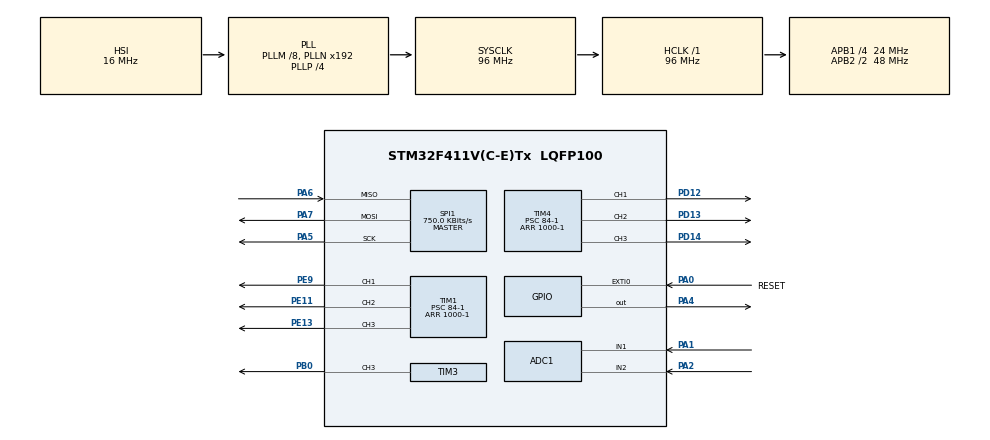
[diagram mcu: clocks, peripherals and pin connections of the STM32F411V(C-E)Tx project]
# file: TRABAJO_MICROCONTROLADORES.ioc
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ADC1.Channel-0\#ChannelRegularConversion=ADC_CHANNEL_1
ADC1.Channel-1\#ChannelRegularConversion=ADC_CHANNEL_2
ADC1.NbrOfConversion=2
ADC1.NbrOfConversionFlag=1
ADC1.Rank-0\#ChannelRegularConversion=1
ADC1.Rank-1\#ChannelRegularConversion=2
ADC1.SamplingTime-0\#ChannelRegularConversion=ADC_SAMPLETIME_84CYCLES
ADC1.SamplingTime-1\#ChannelRegularConversion=ADC_SAMPLETIME_84CYCLES
ADC1.ScanConvMode=ENABLE
ADC1.master=1
Mcu.Family=STM32F4
Mcu.Name=STM32F411V(C-E)Tx
Mcu.Package=LQFP100
NVIC.EXTI0_IRQn=true\:0\:0\:false\:false\:true\:true\:true\:true
NVIC.PriorityGroup=NVIC_PRIORITYGROUP_0
PA0-WKUP.GPIO_Label=RESET
PA0-WKUP.Signal=GPXTI0
PA1.Signal=ADCx_IN1
PA2.Signal=ADCx_IN2
PA4.Signal=GPIO_Output
PA5.Mode=Full_Duplex_Master
PA5.Signal=SPI1_SCK
PA6.Mode=Full_Duplex_Master
PA6.Signal=SPI1_MISO
PA7.Mode=Full_Duplex_Master
PA7.Signal=SPI1_MOSI
PB0.Signal=S_TIM3_CH3
PD12.Signal=S_TIM4_CH1
PD13.Signal=S_TIM4_CH2
PD14.Signal=S_TIM4_CH3
PE11.Signal=S_TIM1_CH2
PE13.Signal=S_TIM1_CH3
PE9.Signal=S_TIM1_CH1
ProjectManager.HeapSize=0x200
ProjectManager.StackSize=0x400
ProjectManager.TargetToolchain=STM32CubeIDE
RCC.48MHZClocksFreq_Value=48000000
RCC.AHBFreq_Value=96000000
RCC.APB1CLKDivider=RCC_HCLK_DIV4
RCC.APB1Freq_Value=24000000
RCC.APB1TimFreq_Value=48000000
RCC.APB2CLKDivider=RCC_HCLK_DIV2
RCC.APB2Freq_Value=48000000
RCC.APB2TimFreq_Value=96000000
RCC.CortexFreq_Value=96000000
RCC.HCLKFreq_Value=96000000
RCC.HSE_VALUE=8000000
RCC.HSI_VALUE=16000000
RCC.LSE_VALUE=32768
RCC.PLLI2SM=5
RCC.PLLI2SN=200
RCC.PLLM=8
RCC.PLLP=RCC_PLLP_DIV4
RCC.PLLQ=8
RCC.SYSCLKFreq_VALUE=96000000
RCC.SYSCLKSource=RCC_SYSCLKSOURCE_PLLCLK
RCC.VCOOutputFreq_Value=384000000
SH.ADCx_IN1.0=ADC1_IN1,IN1
SH.ADCx_IN2.0=ADC1_IN2,IN2
SH.S_TIM1_CH1.0=TIM1_CH1,PWM Generation1 CH1
SH.S_TIM1_CH2.0=TIM1_CH2,PWM Generation2 CH2
SH.S_TIM1_CH3.0=TIM1_CH3,PWM Generation3 CH3
SH.S_TIM3_CH3.0=TIM3_CH3,PWM Generation3 CH3
SH.S_TIM4_CH1.0=TIM4_CH1,PWM Generation1 CH1
SH.S_TIM4_CH2.0=TIM4_CH2,PWM Generation2 CH2
SH.S_TIM4_CH3.0=TIM4_CH3,PWM Generation3 CH3
SPI1.BaudRatePrescaler=SPI_BAUDRATEPRESCALER_64
SPI1.CalculateBaudRate=750.0 KBits/s
SPI1.Direction=SPI_DIRECTION_2LINES
SPI1.Mode=SPI_MODE_MASTER
SPI1.VirtualType=VM_MASTER
TIM1.AutoReloadPreload=TIM_AUTORELOAD_PRELOAD_ENABLE
TIM1.Channel-PWM\ Generation1\ CH1=TIM_CHANNEL_1
TIM1.Channel-PWM\ Generation2\ CH2=TIM_CHANNEL_2
TIM1.Channel-PWM\ Generation3\ CH3=TIM_CHANNEL_3
TIM1.Period=1000-1
TIM1.Prescaler=84-1
TIM3.AutoReloadPreload=TIM_AUTORELOAD_PRELOAD_ENABLE
TIM3.Channel-PWM\ Generation3\ CH3=TIM_CHANNEL_3
TIM3.Period=1000-1
TIM3.Prescaler=84-1
TIM4.AutoReloadPreload=TIM_AUTORELOAD_PRELOAD_ENABLE
TIM4.Channel-PWM\ Generation1\ CH1=TIM_CHANNEL_1
TIM4.Channel-PWM\ Generation2\ CH2=TIM_CHANNEL_2
TIM4.Channel-PWM\ Generation3\ CH3=TIM_CHANNEL_3
TIM4.Period=1000-1
TIM4.Prescaler=84-1
VP_TIM1_VS_ClockSourceINT.Mode=Internal
VP_TIM3_VS_ClockSourceINT.Mode=Internal
VP_TIM4_VS_ClockSourceINT.Mode=Internal
board=STM32F411E-DISCO

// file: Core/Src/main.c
/* USER CODE BEGIN Header */
/**
  ******************************************************************************
  * @file           : main.c
  * @brief          : Main program body
  ******************************************************************************
  * @attention
  *
  * Copyright (c) 2026 STMicroelectronics.
  * All rights reserved.
  *
  * This software is licensed under terms that can be found in the LICENSE file
  * in the root directory of this software component.
  * If no LICENSE file comes with this software, it is provided AS-IS.
  *
  ******************************************************************************
  */
/* USER CODE END Header */
#include "main.h"
#include "Inputs.h"
#include "Coordinador.h"
#include "Orden_Juego.h"
#include "Zumbador.h"

#include <stdlib.h>

ADC_HandleTypeDef hadc1;

SPI_HandleTypeDef hspi1;

TIM_HandleTypeDef htim1;
TIM_HandleTypeDef htim3;
TIM_HandleTypeDef htim4;

void SystemClock_Config(void);
static void MX_GPIO_Init(void);
static void MX_ADC1_Init(void);
static void MX_TIM1_Init(void);
static void MX_SPI1_Init(void);
static void MX_TIM3_Init(void);
static void MX_TIM4_Init(void);

int main(void)
{

  HAL_Init();
  SystemClock_Config();

  MX_GPIO_Init();
  MX_ADC1_Init();
  MX_TIM1_Init();
  MX_SPI1_Init();
  MX_TIM3_Init();
  MX_TIM4_Init();

  srand(HAL_GetTick());

  Inputs_Init();
  Coordinador_Init();
  Zumbador_Init();
  LEDRGB_Init();
  MAX7219_Init();
  while (1)
  {
    Coordinador_Update();
    HAL_Delay(5);
  }
  /* USER CODE END 3 */
}

void SystemClock_Config(void)
{
  RCC_OscInitTypeDef RCC_OscInitStruct = {0};
  RCC_ClkInitTypeDef RCC_ClkInitStruct = {0};

  /** Configure the main internal regulator output voltage
  */
  __HAL_RCC_PWR_CLK_ENABLE();
  __HAL_PWR_VOLTAGESCALING_CONFIG(PWR_REGULATOR_VOLTAGE_SCALE1);

  /** Initializes the RCC Oscillators according to the specified parameters
  * in the RCC_OscInitTypeDef structure.
  */
  RCC_OscInitStruct.OscillatorType = RCC_OSCILLATORTYPE_HSI;
  RCC_OscInitStruct.HSIState = RCC_HSI_ON;
  RCC_OscInitStruct.HSICalibrationValue = RCC_HSICALIBRATION_DEFAULT;
  RCC_OscInitStruct.PLL.PLLState = RCC_PLL_ON;
  RCC_OscInitStruct.PLL.PLLSource = RCC_PLLSOURCE_HSI;
  RCC_OscInitStruct.PLL.PLLM = 8;
  RCC_OscInitStruct.PLL.PLLN = 192;
  RCC_OscInitStruct.PLL.PLLP = RCC_PLLP_DIV4;
  RCC_OscInitStruct.PLL.PLLQ = 8;
  if (HAL_RCC_OscConfig(&RCC_OscInitStruct) != HAL_OK)
  {
    Error_Handler();
  }

  /** Initializes the CPU, AHB and APB buses clocks
  */
  RCC_ClkInitStruct.ClockType = RCC_CLOCKTYPE_HCLK|RCC_CLOCKTYPE_SYSCLK
                              |RCC_CLOCKTYPE_PCLK1|RCC_CLOCKTYPE_PCLK2;
  RCC_ClkInitStruct.SYSCLKSource = RCC_SYSCLKSOURCE_PLLCLK;
  RCC_ClkInitStruct.AHBCLKDivider = RCC_SYSCLK_DIV1;
  RCC_ClkInitStruct.APB1CLKDivider = RCC_HCLK_DIV4;
  RCC_ClkInitStruct.APB2CLKDivider = RCC_HCLK_DIV2;

  if (HAL_RCC_ClockConfig(&RCC_ClkInitStruct, FLASH_LATENCY_3) != HAL_OK)
  {
    Error_Handler();
  }
}

static void MX_ADC1_Init(void)
{

  ADC_ChannelConfTypeDef sConfig = {0};

  /** Configure the global features of the ADC (Clock, Resolution, Data Alignment and number of conversion)
  */
  hadc1.Instance = ADC1;
  hadc1.Init.ClockPrescaler = ADC_CLOCK_SYNC_PCLK_DIV2;
  hadc1.Init.Resolution = ADC_RESOLUTION_12B;
  hadc1.Init.ScanConvMode = DISABLE;
  hadc1.Init.ContinuousConvMode = DISABLE;
  hadc1.Init.DiscontinuousConvMode = DISABLE;
  hadc1.Init.ExternalTrigConvEdge = ADC_EXTERNALTRIGCONVEDGE_NONE;
  hadc1.Init.ExternalTrigConv = ADC_SOFTWARE_START;
  hadc1.Init.DataAlign = ADC_DATAALIGN_RIGHT;
  hadc1.Init.NbrOfConversion = 1;
  hadc1.Init.DMAContinuousRequests = DISABLE;
  hadc1.Init.EOCSelection = ADC_EOC_SINGLE_CONV;
  if (HAL_ADC_Init(&hadc1) != HAL_OK)
  {
    Error_Handler();
  }

  /** Configure for the selected ADC regular channel its corresponding rank in the sequencer and its sample time.
  */
  sConfig.Channel = ADC_CHANNEL_1;
  sConfig.Rank = 1;
  sConfig.SamplingTime = ADC_SAMPLETIME_84CYCLES;
  if (HAL_ADC_ConfigChannel(&hadc1, &sConfig) != HAL_OK)
  {
    Error_Handler();
  }

  /** Configure for the selected ADC regular channel its corresponding rank in the sequencer and its sample time.
  */
  sConfig.Channel = ADC_CHANNEL_2;
  sConfig.Rank = 2;
  if (HAL_ADC_ConfigChannel(&hadc1, &sConfig) != HAL_OK)
  {
    Error_Handler();
  }

}

static void MX_SPI1_Init(void)
{

  /* SPI1 parameter configuration*/
  hspi1.Instance = SPI1;
  hspi1.Init.Mode = SPI_MODE_MASTER;
  hspi1.Init.Direction = SPI_DIRECTION_2LINES;
  hspi1.Init.DataSize = SPI_DATASIZE_8BIT;
  hspi1.Init.CLKPolarity = SPI_POLARITY_LOW;
  hspi1.Init.CLKPhase = SPI_PHASE_1EDGE;
  hspi1.Init.NSS = SPI_NSS_SOFT;
  hspi1.Init.BaudRatePrescaler = SPI_BAUDRATEPRESCALER_64;
  hspi1.Init.FirstBit = SPI_FIRSTBIT_MSB;
  hspi1.Init.TIMode = SPI_TIMODE_DISABLE;
  hspi1.Init.CRCCalculation = SPI_CRCCALCULATION_DISABLE;
  hspi1.Init.CRCPolynomial = 10;
  if (HAL_SPI_Init(&hspi1) != HAL_OK)
  {
    Error_Handler();
  }

}

static void MX_TIM1_Init(void)
{

  TIM_ClockConfigTypeDef sClockSourceConfig = {0};
  TIM_MasterConfigTypeDef sMasterConfig = {0};
  TIM_OC_InitTypeDef sConfigOC = {0};
  TIM_BreakDeadTimeConfigTypeDef sBreakDeadTimeConfig = {0};

  htim1.Instance = TIM1;
  htim1.Init.Prescaler = 84-1;
  htim1.Init.CounterMode = TIM_COUNTERMODE_UP;
  htim1.Init.Period = 1000-1;
  htim1.Init.ClockDivision = TIM_CLOCKDIVISION_DIV1;
  htim1.Init.RepetitionCounter = 0;
  htim1.Init.AutoReloadPreload = TIM_AUTORELOAD_PRELOAD_ENABLE;
  if (HAL_TIM_Base_Init(&htim1) != HAL_OK)
  {
    Error_Handler();
  }
  sClockSourceConfig.ClockSource = TIM_CLOCKSOURCE_INTERNAL;
  if (HAL_TIM_ConfigClockSource(&htim1, &sClockSourceConfig) != HAL_OK)
  {
    Error_Handler();
  }
  if (HAL_TIM_PWM_Init(&htim1) != HAL_OK)
  {
    Error_Handler();
  }
  sMasterConfig.MasterOutputTrigger = TIM_TRGO_RESET;
  sMasterConfig.MasterSlaveMode = TIM_MASTERSLAVEMODE_DISABLE;
  if (HAL_TIMEx_MasterConfigSynchronization(&htim1, &sMasterConfig) != HAL_OK)
  {
    Error_Handler();
  }
  sConfigOC.OCMode = TIM_OCMODE_PWM1;
  sConfigOC.Pulse = 0;
  sConfigOC.OCPolarity = TIM_OCPOLARITY_HIGH;
  sConfigOC.OCNPolarity = TIM_OCNPOLARITY_HIGH;
  sConfigOC.OCFastMode = TIM_OCFAST_DISABLE;
  sConfigOC.OCIdleState = TIM_OCIDLESTATE_RESET;
  sConfigOC.OCNIdleState = TIM_OCNIDLESTATE_RESET;
  if (HAL_TIM_PWM_ConfigChannel(&htim1, &sConfigOC, TIM_CHANNEL_1) != HAL_OK)
  {
    Error_Handler();
  }
  if (HAL_TIM_PWM_ConfigChannel(&htim1, &sConfigOC, TIM_CHANNEL_2) != HAL_OK)
  {
    Error_Handler();
  }
  if (HAL_TIM_PWM_ConfigChannel(&htim1, &sConfigOC, TIM_CHANNEL_3) != HAL_OK)
  {
    Error_Handler();
  }
  sBreakDeadTimeConfig.OffStateRunMode = TIM_OSSR_DISABLE;
  sBreakDeadTimeConfig.OffStateIDLEMode = TIM_OSSI_DISABLE;
  sBreakDeadTimeConfig.LockLevel = TIM_LOCKLEVEL_OFF;
  sBreakDeadTimeConfig.DeadTime = 0;
  sBreakDeadTimeConfig.BreakState = TIM_BREAK_DISABLE;
  sBreakDeadTimeConfig.BreakPolarity = TIM_BREAKPOLARITY_HIGH;
  sBreakDeadTimeConfig.AutomaticOutput = TIM_AUTOMATICOUTPUT_DISABLE;
  if (HAL_TIMEx_ConfigBreakDeadTime(&htim1, &sBreakDeadTimeConfig) != HAL_OK)
  {
    Error_Handler();
  }
  HAL_TIM_MspPostInit(&htim1);

}

static void MX_TIM3_Init(void)
{

  TIM_ClockConfigTypeDef sClockSourceConfig = {0};
  TIM_MasterConfigTypeDef sMasterConfig = {0};
  TIM_OC_InitTypeDef sConfigOC = {0};

  htim3.Instance = TIM3;
  htim3.Init.Prescaler = 84-1;
  htim3.Init.CounterMode = TIM_COUNTERMODE_UP;
  htim3.Init.Period = 1000-1;
  htim3.Init.ClockDivision = TIM_CLOCKDIVISION_DIV1;
  htim3.Init.AutoReloadPreload = TIM_AUTORELOAD_PRELOAD_ENABLE;
  if (HAL_TIM_Base_Init(&htim3) != HAL_OK)
  {
    Error_Handler();
  }
  sClockSourceConfig.ClockSource = TIM_CLOCKSOURCE_INTERNAL;
  if (HAL_TIM_ConfigClockSource(&htim3, &sClockSourceConfig) != HAL_OK)
  {
    Error_Handler();
  }
  if (HAL_TIM_PWM_Init(&htim3) != HAL_OK)
  {
    Error_Handler();
  }
  sMasterConfig.MasterOutputTrigger = TIM_TRGO_RESET;
  sMasterConfig.MasterSlaveMode = TIM_MASTERSLAVEMODE_DISABLE;
  if (HAL_TIMEx_MasterConfigSynchronization(&htim3, &sMasterConfig) != HAL_OK)
  {
    Error_Handler();
  }
  sConfigOC.OCMode = TIM_OCMODE_PWM1;
  sConfigOC.Pulse = 0;
  sConfigOC.OCPolarity = TIM_OCPOLARITY_HIGH;
  sConfigOC.OCFastMode = TIM_OCFAST_DISABLE;
  if (HAL_TIM_PWM_ConfigChannel(&htim3, &sConfigOC, TIM_CHANNEL_3) != HAL_OK)
  {
    Error_Handler();
  }
  HAL_TIM_MspPostInit(&htim3);

}

static void MX_TIM4_Init(void)
{

  TIM_ClockConfigTypeDef sClockSourceConfig = {0};
  TIM_MasterConfigTypeDef sMasterConfig = {0};
  TIM_OC_InitTypeDef sConfigOC = {0};

  htim4.Instance = TIM4;
  htim4.Init.Prescaler = 84-1;
  htim4.Init.CounterMode = TIM_COUNTERMODE_UP;
  htim4.Init.Period = 1000-1;
  htim4.Init.ClockDivision = TIM_CLOCKDIVISION_DIV1;
  htim4.Init.AutoReloadPreload = TIM_AUTORELOAD_PRELOAD_ENABLE;
  if (HAL_TIM_Base_Init(&htim4) != HAL_OK)
  {
    Error_Handler();
  }
  sClockSourceConfig.ClockSource = TIM_CLOCKSOURCE_INTERNAL;
  if (HAL_TIM_ConfigClockSource(&htim4, &sClockSourceConfig) != HAL_OK)
  {
    Error_Handler();
  }
  if (HAL_TIM_PWM_Init(&htim4) != HAL_OK)
  {
    Error_Handler();
  }
  sMasterConfig.MasterOutputTrigger = TIM_TRGO_RESET;
  sMasterConfig.MasterSlaveMode = TIM_MASTERSLAVEMODE_DISABLE;
  if (HAL_TIMEx_MasterConfigSynchronization(&htim4, &sMasterConfig) != HAL_OK)
  {
    Error_Handler();
  }
  sConfigOC.OCMode = TIM_OCMODE_PWM1;
  sConfigOC.Pulse = 0;
  sConfigOC.OCPolarity = TIM_OCPOLARITY_HIGH;
  sConfigOC.OCFastMode = TIM_OCFAST_DISABLE;
  if (HAL_TIM_PWM_ConfigChannel(&htim4, &sConfigOC, TIM_CHANNEL_1) != HAL_OK)
  {
    Error_Handler();
  }
  if (HAL_TIM_PWM_ConfigChannel(&htim4, &sConfigOC, TIM_CHANNEL_2) != HAL_OK)
  {
    Error_Handler();
  }
  if (HAL_TIM_PWM_ConfigChannel(&htim4, &sConfigOC, TIM_CHANNEL_3) != HAL_OK)
  {
    Error_Handler();
  }
  HAL_TIM_MspPostInit(&htim4);

}

static void MX_GPIO_Init(void)
{
  GPIO_InitTypeDef GPIO_InitStruct = {0};

  /* GPIO Ports Clock Enable */
  __HAL_RCC_GPIOA_CLK_ENABLE();
  __HAL_RCC_GPIOB_CLK_ENABLE();
  __HAL_RCC_GPIOE_CLK_ENABLE();
  __HAL_RCC_GPIOD_CLK_ENABLE();

  /*Configure GPIO pin Output Level */
  HAL_GPIO_WritePin(GPIOA, GPIO_PIN_4, GPIO_PIN_RESET);

  /*Configure GPIO pin : RESET_Pin */
  GPIO_InitStruct.Pin = RESET_Pin;
  GPIO_InitStruct.Mode = GPIO_MODE_IT_FALLING;
  GPIO_InitStruct.Pull = GPIO_PULLUP;
  HAL_GPIO_Init(RESET_GPIO_Port, &GPIO_InitStruct);

  /*Configure GPIO pin : PA4 */
  GPIO_InitStruct.Pin = GPIO_PIN_4;
  GPIO_InitStruct.Mode = GPIO_MODE_OUTPUT_PP;
  GPIO_InitStruct.Pull = GPIO_PULLUP;
  GPIO_InitStruct.Speed = GPIO_SPEED_FREQ_LOW;
  HAL_GPIO_Init(GPIOA, &GPIO_InitStruct);

  /* EXTI interrupt init*/
  HAL_NVIC_SetPriority(EXTI0_IRQn, 0, 0);
  HAL_NVIC_EnableIRQ(EXTI0_IRQn);

}

void Error_Handler(void)
{
  /* USER CODE BEGIN Error_Handler_Debug */
  /* User can add his own implementation to report the HAL error return state */
  __disable_irq();
  while (1)
  {
	  Buzzer_On(2000);

  }
  /* USER CODE END Error_Handler_Debug */
}
